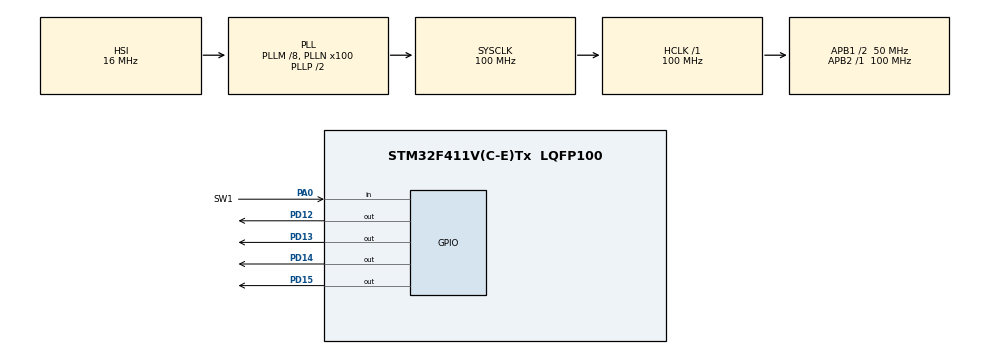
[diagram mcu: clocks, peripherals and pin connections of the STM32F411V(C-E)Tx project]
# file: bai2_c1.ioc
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Mcu.Family=STM32F4
Mcu.Name=STM32F411V(C-E)Tx
Mcu.Package=LQFP100
NVIC.PriorityGroup=NVIC_PRIORITYGROUP_4
PA0-WKUP.GPIO_Label=SW1
PA0-WKUP.Signal=GPIO_Input
PC14-OSC32_IN.Mode=LSE-External-Oscillator
PC14-OSC32_IN.Signal=RCC_OSC32_IN
PC15-OSC32_OUT.Mode=LSE-External-Oscillator
PC15-OSC32_OUT.Signal=RCC_OSC32_OUT
PD12.Signal=GPIO_Output
PD13.Signal=GPIO_Output
PD14.Signal=GPIO_Output
PD15.Signal=GPIO_Output
PH0\ -\ OSC_IN.Mode=HSE-External-Oscillator
PH0\ -\ OSC_IN.Signal=RCC_OSC_IN
PH1\ -\ OSC_OUT.Mode=HSE-External-Oscillator
PH1\ -\ OSC_OUT.Signal=RCC_OSC_OUT
ProjectManager.HeapSize=0x200
ProjectManager.StackSize=0x400
ProjectManager.TargetToolchain=MDK-ARM V5.32
RCC.48MHZClocksFreq_Value=50000000
RCC.AHBFreq_Value=100000000
RCC.APB1CLKDivider=RCC_HCLK_DIV2
RCC.APB1Freq_Value=50000000
RCC.APB1TimFreq_Value=100000000
RCC.APB2Freq_Value=100000000
RCC.APB2TimFreq_Value=100000000
RCC.CortexFreq_Value=100000000
RCC.HCLKFreq_Value=100000000
RCC.HSE_VALUE=25000000
RCC.HSI_VALUE=16000000
RCC.PLLM=8
RCC.PLLN=100
RCC.SYSCLKFreq_VALUE=100000000
RCC.SYSCLKSource=RCC_SYSCLKSOURCE_PLLCLK
RCC.VCOOutputFreq_Value=200000000
board=custom

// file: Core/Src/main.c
/* USER CODE BEGIN Header */
/**
  ******************************************************************************
  * @file           : main.c
  * @brief          : Main program body
  ******************************************************************************
  * @attention
  *
  * Copyright (c) 2023 STMicroelectronics.
  * All rights reserved.
  *
  * This software is licensed under terms that can be found in the LICENSE file
  * in the root directory of this software component.
  * If no LICENSE file comes with this software, it is provided AS-IS.
  *
  ******************************************************************************
  */
/* USER CODE END Header */
#include "main.h"
#include "gpio.h"

/* USER CODE BEGIN PTD */
 uint8_t led=0;
/* USER CODE END PTD */

void SystemClock_Config(void);

/* USER CODE BEGIN 0 */
void nhayled()
	{
		if(HAL_GPIO_ReadPin(SW1_GPIO_Port,SW1_Pin))
			{
				led = ! led ;

				  HAL_GPIO_WritePin(GPIOD, GPIO_PIN_12|GPIO_PIN_13|GPIO_PIN_14|GPIO_PIN_15,led );

			while(HAL_GPIO_ReadPin(SW1_GPIO_Port,SW1_Pin)){}

			HAL_Delay(200);
			}

	}
/* USER CODE END 0 */

int main(void)
{

  /* MCU Configuration--------------------------------------------------------*/

  /* Reset of all peripherals, Initializes the Flash interface and the Systick. */
  HAL_Init();

  /* Configure the system clock */
  SystemClock_Config();

  /* Initialize all configured peripherals */
  MX_GPIO_Init();

  /* Infinite loop */
  while (1)
  {

    /* USER CODE BEGIN 3 */

		nhayled();
  }
  /* USER CODE END 3 */
}

void SystemClock_Config(void)
{
  RCC_OscInitTypeDef RCC_OscInitStruct = {0};
  RCC_ClkInitTypeDef RCC_ClkInitStruct = {0};

  /** Configure the main internal regulator output voltage
  */
  __HAL_RCC_PWR_CLK_ENABLE();
  __HAL_PWR_VOLTAGESCALING_CONFIG(PWR_REGULATOR_VOLTAGE_SCALE1);

  /** Initializes the RCC Oscillators according to the specified parameters
  * in the RCC_OscInitTypeDef structure.
  */
  RCC_OscInitStruct.OscillatorType = RCC_OSCILLATORTYPE_HSI;
  RCC_OscInitStruct.HSIState = RCC_HSI_ON;
  RCC_OscInitStruct.HSICalibrationValue = RCC_HSICALIBRATION_DEFAULT;
  RCC_OscInitStruct.PLL.PLLState = RCC_PLL_ON;
  RCC_OscInitStruct.PLL.PLLSource = RCC_PLLSOURCE_HSI;
  RCC_OscInitStruct.PLL.PLLM = 8;
  RCC_OscInitStruct.PLL.PLLN = 100;
  RCC_OscInitStruct.PLL.PLLP = RCC_PLLP_DIV2;
  RCC_OscInitStruct.PLL.PLLQ = 4;
  if (HAL_RCC_OscConfig(&RCC_OscInitStruct) != HAL_OK)
  {
    Error_Handler();
  }

  /** Initializes the CPU, AHB and APB buses clocks
  */
  RCC_ClkInitStruct.ClockType = RCC_CLOCKTYPE_HCLK|RCC_CLOCKTYPE_SYSCLK
                              |RCC_CLOCKTYPE_PCLK1|RCC_CLOCKTYPE_PCLK2;
  RCC_ClkInitStruct.SYSCLKSource = RCC_SYSCLKSOURCE_PLLCLK;
  RCC_ClkInitStruct.AHBCLKDivider = RCC_SYSCLK_DIV1;
  RCC_ClkInitStruct.APB1CLKDivider = RCC_HCLK_DIV2;
  RCC_ClkInitStruct.APB2CLKDivider = RCC_HCLK_DIV1;

  if (HAL_RCC_ClockConfig(&RCC_ClkInitStruct, FLASH_LATENCY_3) != HAL_OK)
  {
    Error_Handler();
  }
}

void Error_Handler(void)
{
  __disable_irq();
  while (1)
  {
  }
}
